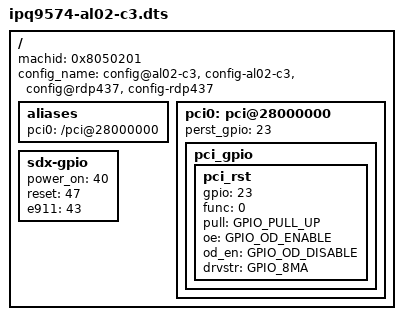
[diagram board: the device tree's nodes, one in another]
/*
 * Copyright (c) 2016-2021, The Linux Foundation. All rights reserved.
 * Copyright (c) 2021 Qualcomm Innovation Center, Inc. All rights reserved.
 *
 * This program is free software; you can redistribute it and/or modify
 * it under the terms of the GNU General Public License version 2 and
 * only version 2 as published by the Free Software Foundation.
 *
 * This program is distributed in the hope that it will be useful,
 * but WITHOUT ANY WARRANTY; without even the implied warranty of
 * MERCHANTABILITY or FITNESS FOR A PARTICULAR PURPOSE.  See the
 * GNU General Public License for more details.
 */

/dts-v1/;
#include "ipq9574-al02-c2.dts"
/ {
	machid = <0x8050201>;
	config_name = "config@al02-c3", "config-al02-c3", "config@rdp437", "config-rdp437";

	aliases {
		pci0 = "/pci@28000000";
	};

	pci0: pci@28000000 {
		status = "ok";
		perst_gpio = <23>;
		pci_gpio {
			pci_rst {
				gpio = <23>;
				func = <0>;
				pull = <GPIO_PULL_UP>;
				oe = <GPIO_OD_ENABLE>;
				od_en = <GPIO_OD_DISABLE>;
				drvstr = <GPIO_8MA>;
			};
		};
	};

	/delete-node/ pci@18000000;

	sdx-gpio {
		power_on = <40>;
		reset = <47>;
		e911 = <43>;
	};
};
